# iostr731 register map
Registers are 16-bit, access not given, no defined reset value unless marked. A register's access mark holds for its fields unless they carry their own. Addresses are absolute; registers are grouped by the start of their names; [hi:lo] are bit positions; {n}, {i} and the like mark numbered series; 'fields as' and 'values as' point back to an identical list.

## CAN1
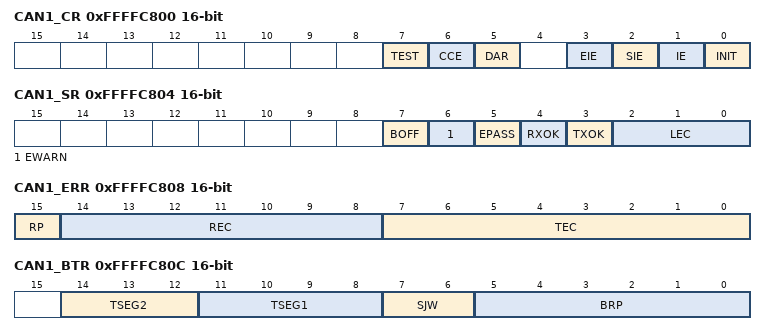
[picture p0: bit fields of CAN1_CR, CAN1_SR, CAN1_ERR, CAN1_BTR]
0xFFFFC800 CAN1_CR
  [7] TEST, [6] CCE, [5] DAR, [3] EIE, [2] SIE, [1] IE, [0] INIT
0xFFFFC804 CAN1_SR
  [7] BOFF, [6] EWARN, [5] EPASS, [4] RXOK, [3] TXOK, [2:0] LEC
0xFFFFC808 CAN1_ERR
  [15] RP, [14:8] REC, [7:0] TEC
0xFFFFC80C CAN1_BTR
  [14:12] TSEG2, [11:8] TSEG1, [7:6] SJW, [5:0] BRP
0xFFFFC810 CAN1_IDR
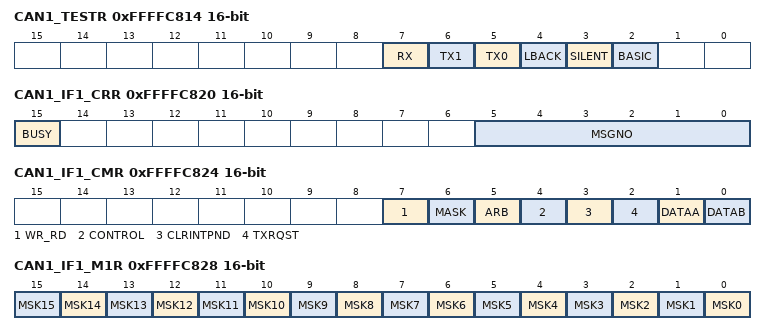
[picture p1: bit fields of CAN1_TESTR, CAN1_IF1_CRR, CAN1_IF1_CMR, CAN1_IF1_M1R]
0xFFFFC814 CAN1_TESTR
  [7] RX, [6] TX1, [5] TX0, [4] LBACK, [3] SILENT, [2] BASIC
0xFFFFC818 CAN1_BRPR
  [3:0] BRPE
0xFFFFC820 CAN1_IF1_CRR
  [15] BUSY, [5:0] MSGNO
0xFFFFC824 CAN1_IF1_CMR
  [7] WR_RD, [6] MASK, [5] ARB, [4] CONTROL, [3] CLRINTPND, [2] TXRQST, [1] DATAA, [0] DATAB
0xFFFFC828 CAN1_IF1_M1R
  [n] MSK{n} (n=0..15)
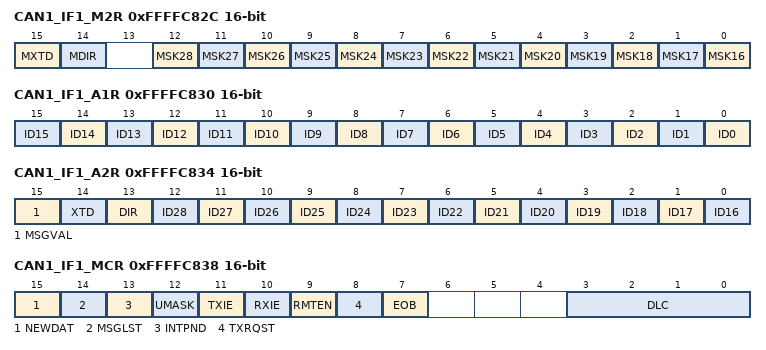
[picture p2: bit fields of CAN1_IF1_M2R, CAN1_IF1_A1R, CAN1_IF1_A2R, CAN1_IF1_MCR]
0xFFFFC82C CAN1_IF1_M2R
  [15] MXTD, [14] MDIR, [n-16] MSK{n} (n=16..28)
0xFFFFC830 CAN1_IF1_A1R
  [n] ID{n} (n=0..15)
0xFFFFC834 CAN1_IF1_A2R
  [15] MSGVAL, [14] XTD, [13] DIR, [n-16] ID{n} (n=16..28)
0xFFFFC838 CAN1_IF1_MCR
  [15] NEWDAT, [14] MSGLST, [13] INTPND, [12] UMASK, [11] TXIE, [10] RXIE, [9] RMTEN, [8] TXRQST, [7] EOB, [3:0] DLC
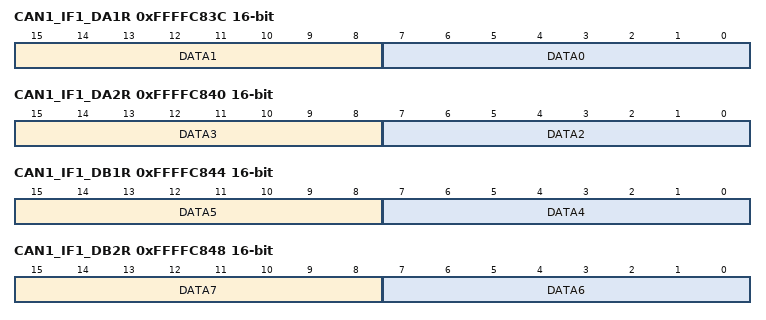
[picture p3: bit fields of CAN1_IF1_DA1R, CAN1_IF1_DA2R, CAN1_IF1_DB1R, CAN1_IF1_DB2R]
0xFFFFC83C CAN1_IF1_DA1R
  [15:8] DATA1, [7:0] DATA0
0xFFFFC840 CAN1_IF1_DA2R
  [15:8] DATA3, [7:0] DATA2
0xFFFFC844 CAN1_IF1_DB1R
  [15:8] DATA5, [7:0] DATA4
0xFFFFC848 CAN1_IF1_DB2R
  [15:8] DATA7, [7:0] DATA6
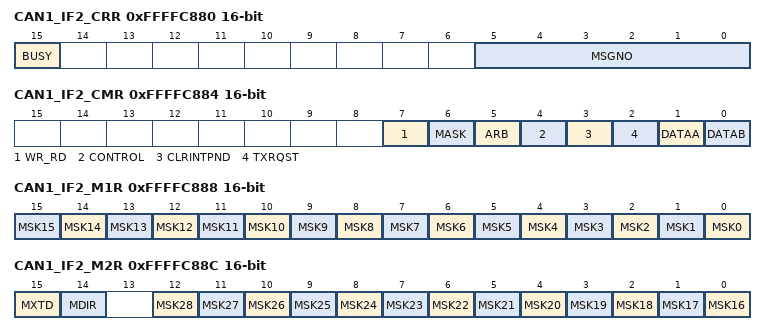
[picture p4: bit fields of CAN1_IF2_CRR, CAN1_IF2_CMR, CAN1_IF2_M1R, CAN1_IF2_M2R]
0xFFFFC880 CAN1_IF2_CRR
  [15] BUSY, [5:0] MSGNO
0xFFFFC884 CAN1_IF2_CMR
  fields as CAN1_IF1_CMR
0xFFFFC888 CAN1_IF2_M1R
  [n] MSK{n} (n=0..15)
0xFFFFC88C CAN1_IF2_M2R
  [15] MXTD, [14] MDIR, [n-16] MSK{n} (n=16..28)
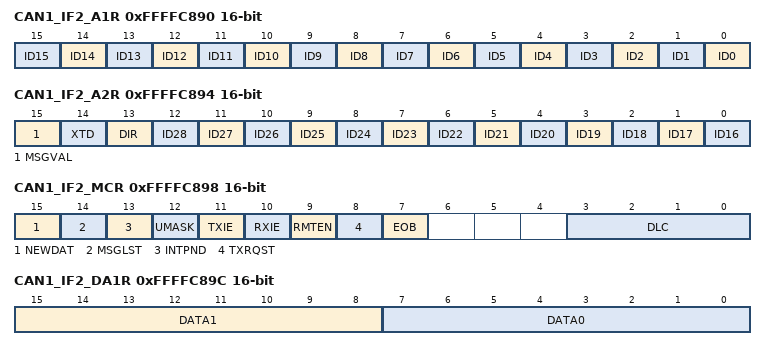
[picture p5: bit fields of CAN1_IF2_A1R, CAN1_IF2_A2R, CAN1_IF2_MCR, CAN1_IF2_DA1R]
0xFFFFC890 CAN1_IF2_A1R
  [n] ID{n} (n=0..15)
0xFFFFC894 CAN1_IF2_A2R
  [15] MSGVAL, [14] XTD, [13] DIR, [n-16] ID{n} (n=16..28)
0xFFFFC898 CAN1_IF2_MCR
  fields as CAN1_IF1_MCR
0xFFFFC89C CAN1_IF2_DA1R
  [15:8] DATA1, [7:0] DATA0
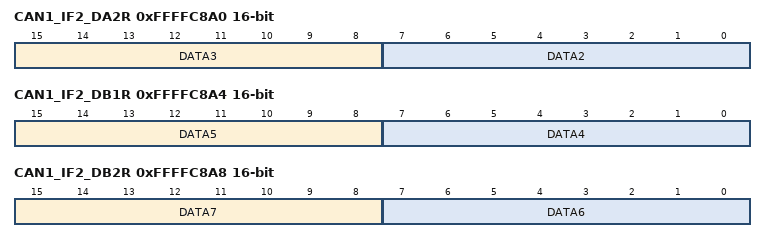
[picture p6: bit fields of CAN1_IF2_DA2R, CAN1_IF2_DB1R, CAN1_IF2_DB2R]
0xFFFFC8A0 CAN1_IF2_DA2R
  [15:8] DATA3, [7:0] DATA2
0xFFFFC8A4 CAN1_IF2_DB1R
  [15:8] DATA5, [7:0] DATA4
0xFFFFC8A8 CAN1_IF2_DB2R
  [15:8] DATA7, [7:0] DATA6
0xFFFFC900 CAN1_TXR1R 32-bit
0xFFFFC904 CAN1_TXR2R 32-bit
0xFFFFC920 CAN1_ND1R 32-bit
0xFFFFC924 CAN1_ND2R 32-bit
0xFFFFC940 CAN1_IP1R 32-bit
0xFFFFC944 CAN1_IP2R 32-bit
0xFFFFC960 CAN1_MV1R 32-bit
0xFFFFC964 CAN1_MV2R 32-bit

## CAN2
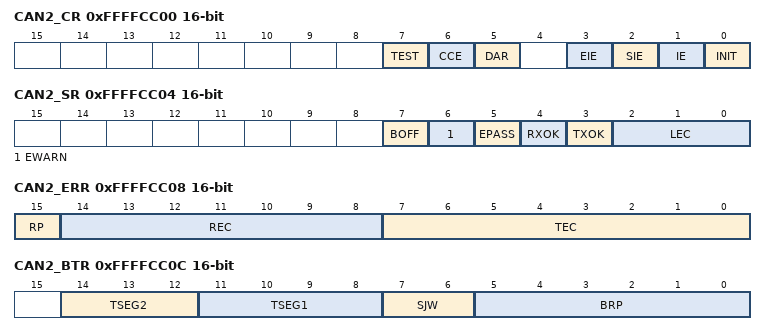
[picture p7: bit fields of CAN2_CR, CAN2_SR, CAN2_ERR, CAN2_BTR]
0xFFFFCC00 CAN2_CR
  [7] TEST, [6] CCE, [5] DAR, [3] EIE, [2] SIE, [1] IE, [0] INIT
0xFFFFCC04 CAN2_SR
  [7] BOFF, [6] EWARN, [5] EPASS, [4] RXOK, [3] TXOK, [2:0] LEC
0xFFFFCC08 CAN2_ERR
  [15] RP, [14:8] REC, [7:0] TEC
0xFFFFCC0C CAN2_BTR
  [14:12] TSEG2, [11:8] TSEG1, [7:6] SJW, [5:0] BRP
0xFFFFCC10 CAN2_IDR
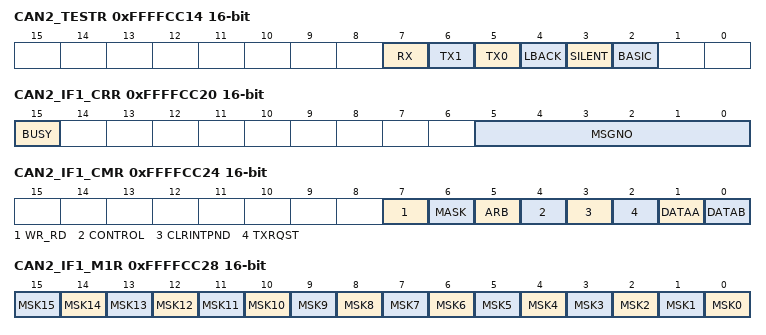
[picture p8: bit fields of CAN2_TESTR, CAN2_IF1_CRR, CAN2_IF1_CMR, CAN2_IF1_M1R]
0xFFFFCC14 CAN2_TESTR
  [7] RX, [6] TX1, [5] TX0, [4] LBACK, [3] SILENT, [2] BASIC
0xFFFFCC18 CAN2_BRPR
  [3:0] BRPE
0xFFFFCC20 CAN2_IF1_CRR
  [15] BUSY, [5:0] MSGNO
0xFFFFCC24 CAN2_IF1_CMR
  [7] WR_RD, [6] MASK, [5] ARB, [4] CONTROL, [3] CLRINTPND, [2] TXRQST, [1] DATAA, [0] DATAB
0xFFFFCC28 CAN2_IF1_M1R
  [n] MSK{n} (n=0..15)
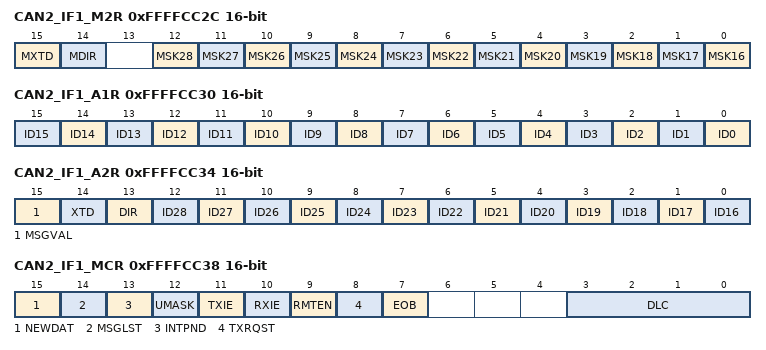
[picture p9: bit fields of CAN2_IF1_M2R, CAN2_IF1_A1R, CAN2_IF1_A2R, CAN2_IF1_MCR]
0xFFFFCC2C CAN2_IF1_M2R
  [15] MXTD, [14] MDIR, [n-16] MSK{n} (n=16..28)
0xFFFFCC30 CAN2_IF1_A1R
  [n] ID{n} (n=0..15)
0xFFFFCC34 CAN2_IF1_A2R
  [15] MSGVAL, [14] XTD, [13] DIR, [n-16] ID{n} (n=16..28)
0xFFFFCC38 CAN2_IF1_MCR
  [15] NEWDAT, [14] MSGLST, [13] INTPND, [12] UMASK, [11] TXIE, [10] RXIE, [9] RMTEN, [8] TXRQST, [7] EOB, [3:0] DLC
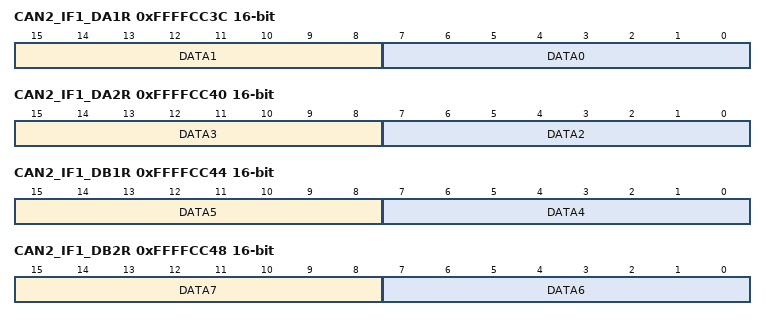
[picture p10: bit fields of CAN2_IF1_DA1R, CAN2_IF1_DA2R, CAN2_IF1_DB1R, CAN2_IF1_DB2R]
0xFFFFCC3C CAN2_IF1_DA1R
  [15:8] DATA1, [7:0] DATA0
0xFFFFCC40 CAN2_IF1_DA2R
  [15:8] DATA3, [7:0] DATA2
0xFFFFCC44 CAN2_IF1_DB1R
  [15:8] DATA5, [7:0] DATA4
0xFFFFCC48 CAN2_IF1_DB2R
  [15:8] DATA7, [7:0] DATA6
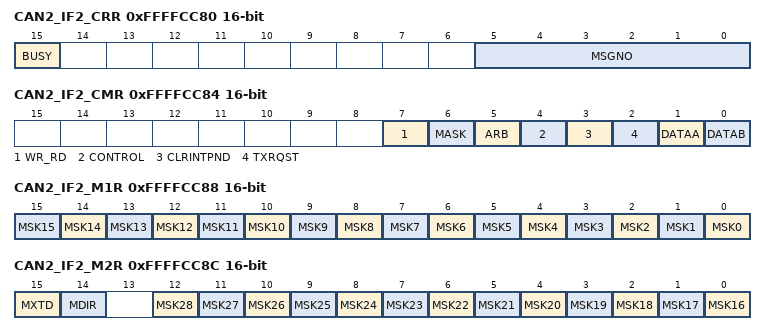
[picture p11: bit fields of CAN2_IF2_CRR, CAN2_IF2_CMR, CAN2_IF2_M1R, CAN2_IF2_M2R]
0xFFFFCC80 CAN2_IF2_CRR
  [15] BUSY, [5:0] MSGNO
0xFFFFCC84 CAN2_IF2_CMR
  fields as CAN2_IF1_CMR
0xFFFFCC88 CAN2_IF2_M1R
  [n] MSK{n} (n=0..15)
0xFFFFCC8C CAN2_IF2_M2R
  [15] MXTD, [14] MDIR, [n-16] MSK{n} (n=16..28)
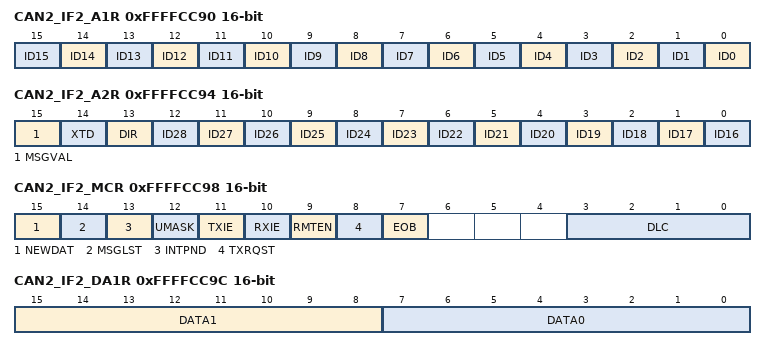
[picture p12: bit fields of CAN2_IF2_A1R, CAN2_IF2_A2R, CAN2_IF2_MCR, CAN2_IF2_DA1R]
0xFFFFCC90 CAN2_IF2_A1R
  [n] ID{n} (n=0..15)
0xFFFFCC94 CAN2_IF2_A2R
  [15] MSGVAL, [14] XTD, [13] DIR, [n-16] ID{n} (n=16..28)
0xFFFFCC98 CAN2_IF2_MCR
  fields as CAN2_IF1_MCR
0xFFFFCC9C CAN2_IF2_DA1R
  [15:8] DATA1, [7:0] DATA0
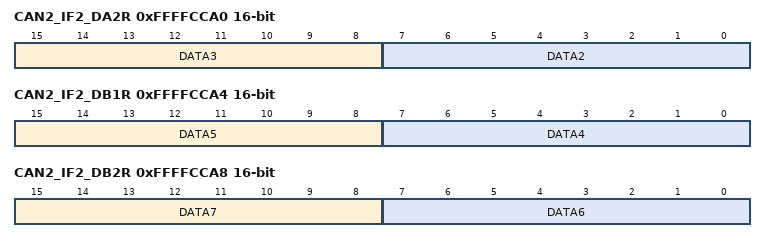
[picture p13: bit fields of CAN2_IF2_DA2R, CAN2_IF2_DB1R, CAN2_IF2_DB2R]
0xFFFFCCA0 CAN2_IF2_DA2R
  [15:8] DATA3, [7:0] DATA2
0xFFFFCCA4 CAN2_IF2_DB1R
  [15:8] DATA5, [7:0] DATA4
0xFFFFCCA8 CAN2_IF2_DB2R
  [15:8] DATA7, [7:0] DATA6
0xFFFFCD00 CAN2_TXR1R 32-bit
0xFFFFCD04 CAN2_TXR2R 32-bit
0xFFFFCD20 CAN2_ND1R 32-bit
0xFFFFCD24 CAN2_ND2R 32-bit
0xFFFFCD40 CAN2_IP1R 32-bit
0xFFFFCD44 CAN2_IP2R 32-bit
0xFFFFCD60 CAN2_MV1R 32-bit
0xFFFFCD64 CAN2_MV2R 32-bit
